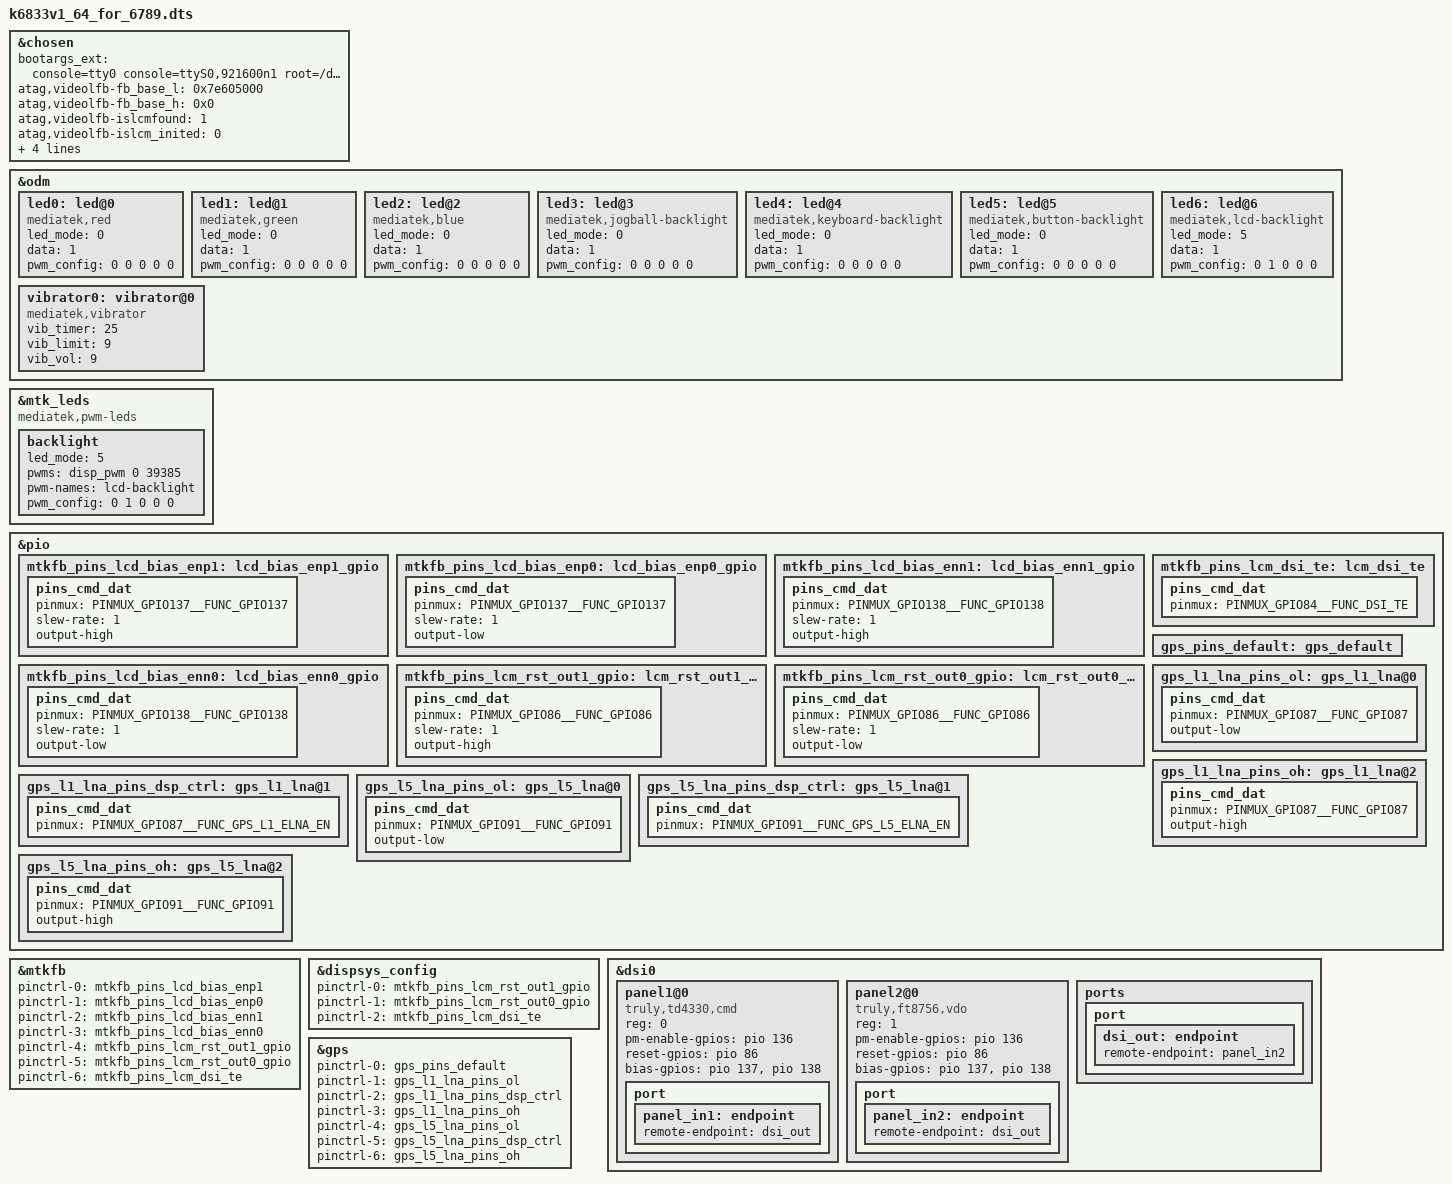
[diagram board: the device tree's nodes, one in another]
// SPDX-License-Identifier: (GPL-2.0 OR MIT)
/*
 * Copyright (C) 2021 MediaTek Inc.
 */
/dts-v1/;
/plugin/;
#include <dt-bindings/interrupt-controller/arm-gic.h>
#include <dt-bindings/interrupt-controller/irq.h>
#include <dt-bindings/pinctrl/mt6833-pinfunc.h>

&chosen {
	bootargs_ext = "console=tty0 console=ttyS0,921600n1 root=/dev/ram \
loglevel=8 \
initcall_debug=1";
	atag,videolfb-fb_base_l = <0x7e605000>;
	atag,videolfb-fb_base_h = <0x0>;
	atag,videolfb-islcmfound = <1>;
	atag,videolfb-islcm_inited = <0>;
	atag,videolfb-fps= <6000>;
	atag,videolfb-vramSize= <0x1be0000>;
	atag,videolfb-lcmname=
		"nt35595_fhd_dsi_cmd_truly_nt50358_drv";
};

&odm {
	led0:led@0 {
		compatible = "mediatek,red";
		led_mode = <0>;
		data = <1>;
		pwm_config = <0 0 0 0 0>;
	};
	led1:led@1 {
		compatible = "mediatek,green";
		led_mode = <0>;
		data = <1>;
		pwm_config = <0 0 0 0 0>;
	};
	led2:led@2 {
		compatible = "mediatek,blue";
		led_mode = <0>;
		data = <1>;
		pwm_config = <0 0 0 0 0>;
	};
	led3:led@3 {
		compatible = "mediatek,jogball-backlight";
		led_mode = <0>;
		data = <1>;
		pwm_config = <0 0 0 0 0>;
	};
	led4:led@4 {
		compatible = "mediatek,keyboard-backlight";
		led_mode = <0>;
		data = <1>;
		pwm_config = <0 0 0 0 0>;
	};
	led5:led@5 {
		compatible = "mediatek,button-backlight";
		led_mode = <0>;
		data = <1>;
		pwm_config = <0 0 0 0 0>;
	};
	led6:led@6 {
		compatible = "mediatek,lcd-backlight";
		led_mode = <5>;
		data = <1>;
		pwm_config = <0 1 0 0 0>;
	};
	vibrator0:vibrator@0 {
		compatible = "mediatek,vibrator";
		vib_timer = <25>;
		vib_limit = <9>;
		vib_vol= <9>;
	};
};

&mtk_leds {
	compatible = "mediatek,pwm-leds";
	backlight {
		led_mode = <5>;
		pwms = <&disp_pwm 0 39385>;
		pwm-names = "lcd-backlight";
		pwm_config = <0 1 0 0 0>;
	};
};

#include <k6833v1_64_for_6789/cust.dtsi>
#include "mediatek/cust_mt6833_for_6789_touch_1080x2300.dtsi"

&pio {
	mtkfb_pins_lcd_bias_enp1: lcd_bias_enp1_gpio {
		pins_cmd_dat {
			pinmux = <PINMUX_GPIO137__FUNC_GPIO137>;
			slew-rate = <1>;
			output-high;
		};
	};

	mtkfb_pins_lcd_bias_enp0: lcd_bias_enp0_gpio {
		pins_cmd_dat {
			pinmux = <PINMUX_GPIO137__FUNC_GPIO137>;
			slew-rate = <1>;
			output-low;
		};
	};

	mtkfb_pins_lcd_bias_enn1: lcd_bias_enn1_gpio {
		pins_cmd_dat {
			pinmux = <PINMUX_GPIO138__FUNC_GPIO138>;
			slew-rate = <1>;
			output-high;
		};
	};

	mtkfb_pins_lcd_bias_enn0: lcd_bias_enn0_gpio {
		pins_cmd_dat {
			pinmux = <PINMUX_GPIO138__FUNC_GPIO138>;
			slew-rate = <1>;
			output-low;
		};
	};

	mtkfb_pins_lcm_rst_out1_gpio: lcm_rst_out1_gpio {
		pins_cmd_dat {
			pinmux = <PINMUX_GPIO86__FUNC_GPIO86>;
			slew-rate = <1>;
			output-high;
		};
	};

	mtkfb_pins_lcm_rst_out0_gpio: lcm_rst_out0_gpio {
		pins_cmd_dat {
			pinmux = <PINMUX_GPIO86__FUNC_GPIO86>;
			slew-rate = <1>;
			output-low;
		};
	};
	mtkfb_pins_lcm_dsi_te: lcm_dsi_te {
		pins_cmd_dat {
			pinmux = <PINMUX_GPIO84__FUNC_DSI_TE>;
		};
	};
};

&mtkfb {
	pinctrl-names = "lcd_bias_enp1_gpio", "lcd_bias_enp0_gpio",
		"lcd_bias_enn1_gpio", "lcd_bias_enn0_gpio",
		"lcm_rst_out1_gpio", "lcm_rst_out0_gpio",
		"mode_te_te";
	pinctrl-0 = <&mtkfb_pins_lcd_bias_enp1>;
	pinctrl-1 = <&mtkfb_pins_lcd_bias_enp0>;
	pinctrl-2 = <&mtkfb_pins_lcd_bias_enn1>;
	pinctrl-3 = <&mtkfb_pins_lcd_bias_enn0>;
	pinctrl-4 = <&mtkfb_pins_lcm_rst_out1_gpio>;
	pinctrl-5 = <&mtkfb_pins_lcm_rst_out0_gpio>;
	pinctrl-6 = <&mtkfb_pins_lcm_dsi_te>;
	status = "okay";
};
&dispsys_config {
	pinctrl-names =
		"lcm_rst_out1_gpio", "lcm_rst_out0_gpio",
		"mode_te_te";
	pinctrl-0 = <&mtkfb_pins_lcm_rst_out1_gpio>;
	pinctrl-1 = <&mtkfb_pins_lcm_rst_out0_gpio>;
	pinctrl-2 = <&mtkfb_pins_lcm_dsi_te>;
	status = "okay";
};

&dsi0 {
	status = "okay";
	#address-cells = <1>;
	#size-cells = <0>;
	panel1@0 {
		compatible = "truly,td4330,cmd";
		reg = <0>;
		pm-enable-gpios = <&pio 136 0>;
		reset-gpios = <&pio 86 0>;
		bias-gpios = <&pio 137 0>,
			<&pio 138 0>;
		pinctrl-names = "default";
		port {
			panel_in1: endpoint {
				remote-endpoint = <&dsi_out>;
			};
		};
	};
	panel2@0 {
		compatible = "truly,ft8756,vdo";
		reg = <1>;
		pm-enable-gpios = <&pio 136 0>;
		reset-gpios = <&pio 86 0>;
		bias-gpios = <&pio 137 0>,
			<&pio 138 0>;
		pinctrl-names = "default";
		port {
			panel_in2: endpoint {
				remote-endpoint = <&dsi_out>;
			};
		};
	};
	ports {
		port {
			dsi_out: endpoint {
				remote-endpoint = <&panel_in2>;
			};
		};
	};
};
/* GPS GPIO standardization start */
&pio {
	gps_pins_default: gps_default {
	};
	gps_l1_lna_pins_ol: gps_l1_lna@0 {
		pins_cmd_dat {
			pinmux = <PINMUX_GPIO87__FUNC_GPIO87>;
			output-low;
		};
	};
	gps_l1_lna_pins_dsp_ctrl: gps_l1_lna@1 {
		pins_cmd_dat {
			pinmux = <PINMUX_GPIO87__FUNC_GPS_L1_ELNA_EN>;
		};
	};
	gps_l1_lna_pins_oh: gps_l1_lna@2 {
		pins_cmd_dat {
			pinmux = <PINMUX_GPIO87__FUNC_GPIO87>;
			output-high;
		};
	};
	gps_l5_lna_pins_ol: gps_l5_lna@0 {
		pins_cmd_dat {
			pinmux = <PINMUX_GPIO91__FUNC_GPIO91>;
			output-low;
		};
	};
	gps_l5_lna_pins_dsp_ctrl: gps_l5_lna@1 {
		pins_cmd_dat {
			pinmux = <PINMUX_GPIO91__FUNC_GPS_L5_ELNA_EN>;
		};
	};
	gps_l5_lna_pins_oh: gps_l5_lna@2 {
		pins_cmd_dat {
			pinmux = <PINMUX_GPIO91__FUNC_GPIO91>;
			output-high;
		};
	};
};
&gps {
	pinctrl-names = "default",
		"gps_l1_lna_disable",
		"gps_l1_lna_dsp_ctrl",
		"gps_l1_lna_enable",
		"gps_l5_lna_disable",
		"gps_l5_lna_dsp_ctrl",
		"gps_l5_lna_enable";
	pinctrl-0 = <&gps_pins_default>;
	pinctrl-1 = <&gps_l1_lna_pins_ol>;
	pinctrl-2 = <&gps_l1_lna_pins_dsp_ctrl>;
	pinctrl-3 = <&gps_l1_lna_pins_oh>;
	pinctrl-4 = <&gps_l5_lna_pins_ol>;
	pinctrl-5 = <&gps_l5_lna_pins_dsp_ctrl>;
	pinctrl-6 = <&gps_l5_lna_pins_oh>;
	status = "okay";
};
/* GPS GPIO standardization end */
#include "mediatek/cust_mt6833_camera.dtsi"

/*End of this file, DO NOT ADD ANYTHING HERE*/
